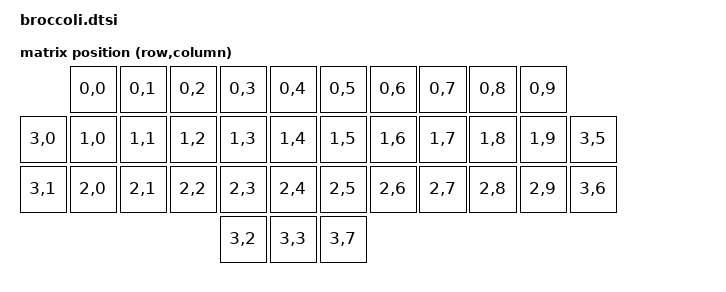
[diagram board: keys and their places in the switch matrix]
// This file was generated from a template. Edit it to match your keyboard.
// See https://zmk.dev/docs/development/hardware-integration/new-shield for more
// instructions.

#include <dt-bindings/zmk/matrix_transform.h>

#include "broccoli-layouts.dtsi"

/ {
    chosen {
        zmk,physical-layout = &default_layout;
    };

    kscan: kscan {
        // If the hardware does not use a switch matrix, change this to the
        // appropriate driver and update the properties below to match.
        // See https://zmk.dev/docs/config/kscan for supported key scan drivers.
        compatible = "zmk,kscan-gpio-matrix";
        // Set this to "col2row" or "row2col" to match the hardware. If using
        // "row2col", change the col-gpios in the _left.overlay and _right.overlay
        // files to (GPIO_ACTIVE_HIGH | GPIO_PULL_DOWN) and the row-gpios here to
        // GPIO_ACTIVE_HIGH.
        diode-direction = "col2row";
        wakeup-source;

        // Replace these comments with the GPIO pins in the matrix.
        // See https://zmk.dev/docs/development/hardware-integration/new-shield#shield-overlays
        // row-gpios
        //     = <&xiao_d 0 (GPIO_ACTIVE_HIGH | GPIO_PULL_DOWN)>
        //     , <&xiao_d 0 (GPIO_ACTIVE_HIGH | GPIO_PULL_DOWN)>
        //    ;
    };

    default_transform: default_transform {
        // See https://zmk.dev/docs/development/hardware-integration/new-shield#matrix-transform
        // for how to configure this
        compatible = "zmk,matrix-transform";
        columns = <10>;
        rows = <4>;

        map = <
                     RC(0, 0) RC(0, 1) RC(0, 2) RC(0, 3) RC(0, 4)    RC(0, 5) RC(0, 6) RC(0, 7) RC(0, 8) RC(0, 9)
            RC(3, 0) RC(1, 0) RC(1, 1) RC(1, 2) RC(1, 3) RC(1, 4)    RC(1, 5) RC(1, 6) RC(1, 7) RC(1, 8) RC(1, 9) RC(3, 5)
            RC(3, 1) RC(2, 0) RC(2, 1) RC(2, 2) RC(2, 3) RC(2, 4)    RC(2, 5) RC(2, 6) RC(2, 7) RC(2, 8) RC(2, 9) RC(3, 6)
                                                RC(3, 2) RC(3, 3)    RC(3, 7)
        >;
    };

    trackball_listener: trackball_listener {
        compatible = "zmk,input-listener";
        status = "disabled";
        device = <&trackball>;
    };
};

&spi0 {
    status = "disabled";
    compatible = "nordic,nrf-spim";
    pinctrl-0 = <&spi0_default>;
    pinctrl-1 = <&spi0_sleep>;
    pinctrl-names = "default", "sleep";
    cs-gpios = <&gpio0 9 GPIO_ACTIVE_LOW>;

    // https://github.com/zmkfirmware/zephyr/blob/v3.5.0%2Bzmk-fixes/include/zephyr/dt-bindings/input/input-event-codes.h#L245
    trackball: trackball@0 {
        status = "disabled";
        compatible = "pixart,pmw3610";
        reg = <0>;
        spi-max-frequency = <2000000>;
        irq-gpios = <&gpio0 10 (GPIO_ACTIVE_LOW | GPIO_PULL_UP)>;
        cpi = <600>;
        evt-type = <INPUT_EV_REL>;
        x-input-code = <INPUT_REL_X>;
        y-input-code = <INPUT_REL_Y>;
    };
};
